# PIC32CX0525SG12084 register map
Vendor: Microchip Technology; Series: 0525SG12; File version: 0
CPU: CM4 r1p0, little endian, no MPU, no FPU, 3 interrupt priority bits, 172 interrupts
Registers are 32-bit, read-write, reset 0x0 unless marked. A register's access mark holds for its fields unless they carry their own. Offsets are from the block's base; [hi:lo] are bit positions.

## PWM0 — The PWM block generates an arbitrary duty cycle output at frequencies from less than 0.1 Hz to 24 MHz
Base 0x40005800; register names take the prefix PWM_
Same registers: PWM1 0x40005810, PWM4 0x40005840, PWM6 0x40005860, PWM7 0x40005870
0x00 CNT_ON — This field determines both the frequency and duty cycle of the PWM signal. Setting this field to a value of n will cause the On time of the PWM to be n+1 cycles of the PWM Clock Source. When this field is set to zero and the PWMX_COUNTER_OFF_TIME is not set to zero, the PWM_OUTPUT is held low (Full Off).
0x04 CNT_OFF reset 0xFFFF — This field determine both the frequency and duty cycle of the PWM signal. Setting this field to a value of n will cause the Off time of the PWM to be n+1 cycles of the PWM Clock Source. When this field is set to zero, the PWM_OUTPUT is held high (Full On).
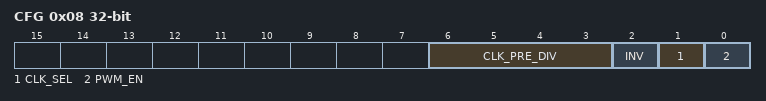
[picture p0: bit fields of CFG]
0x08 CFG — PWMx CONFIGURATION REGISTER
  [6:3] CLK_PRE_DIV — The Clock source for the 16-bit down counter (see PWMx Counter ON Time Register and PWMx Counter OFF Time Register) is determined by bit D1 of this register. The Clock source is then divided by the value of Pre-Divider+1 and the resulting signal determines the rate at which the down counter will be decremented. For example, a Pre-Divider value of 1 divides the input clock by 2 and a value of 2 divides the input clock by 3. A Pre-Divider of 0 will disable the Pre-Divider option.
  [2] INV — 1= PWM_OUTPUT ON State is active low; 0=PWM_OUTPUT ON State is active high.
  [1] CLK_SEL — This bit determines the clock source used by the PWM duty cycle and frequency control logic. 1=CLOCK_LOW. 0=CLOCK_HIGH
  [0] PWM_EN — When the PWM_ENABLE is set to 0 the internal counters are reset and the internal state machine is set to the OFF state. In addition, the PWM_OUTPUT signal is set to the inactive state as determined by the Invert bit. The PWMx Counter ON Time Register and PWMx Counter OFF Time Register are not affected by the PWM_ENABLE bit and may be read and written while the PWM enable bit is 0. 1=Enabled (default); 0=Disabled (gates clocks to save power).

## PS2_0 — The four PS/2 Ports implementation eliminates the need to bit bang I/O ports to generate PS/2 traffic
Base 0x40009000; register names take the prefix PS2_
0x00 TX_DATA wo — Writes to bits 7:0 of this register start a transmission of the data in this register to the peripheral
0x00 RX_DATA ro reset 0xFF — Data received from a peripheral are recorded in this register in bits 7:0.
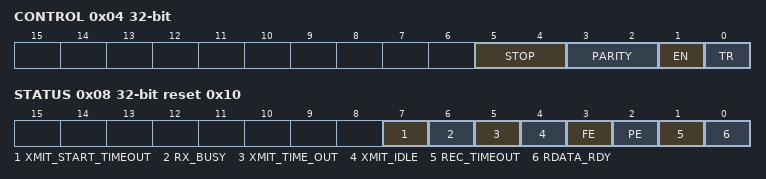
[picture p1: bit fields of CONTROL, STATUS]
0x04 CONTROL — PS2 Control Register
  [5:4] STOP — 00b=Receiver expects an active high stop bit. 01b=Receiver expects an active low stop bit. 10b=Receiver ignores the level of the Stop bit (11th bit is not interpreted as a stop bit). 11b=Reserved.
  [3:2] PARITY — 00b=Receiver expects Odd Parity (default). 01b=Receiver expects Even Parity. 10b=Receiver ignores level of the parity bit (10th bit is not interpreted as a parity bit). 11b=Reserved
  [1] EN — PS/2 Enable. 0=The PS/2 state machine is disabled. 1=The PS/2 state machine is enabled.
  [0] TR — PS/2 Transmit/Receive. 0=The P2/2 channel is enabled to receive data. 1=The PS2 channel is enabled to transmit data.
0x08 STATUS reset 0x10 — PS2 Status Register
  [7] XMIT_START_TIMEOUT — Transmit Start Timeout. 0=No transmit start timeout detected. 1=A start bit was not received within 25 ms following the transmit start event. The transmit start bit time-out condition is also indicated by the XMIT_TIMEOUT bit.
  [6] RX_BUSY — Receive Channel Busy. 0=The channel is idle. 1=The channel is actively receiving PS/2 data
  [5] XMIT_TIME_OUT — Transmitter Time-out. When the XMIT_TIMEOUT bit is set, the PS2_T/R bit is held clear, the PS/2 channel's CLK line is pulled low for a minimum of 300us until the PS/2 Status register is read.
  [4] XMIT_IDLE — Transmitter Idle. 0=The channel is actively transmitting PS/2 data. 1=The channel is not transmitting. A low to high transition on this bit generates a PS2 Activity interrupt.
  [3] FE — Framing Error
  [2] PE — Parity Error
  [1] REC_TIMEOUT — Receive Timeout. The REC_TIMEOUT bit is cleared when the Status Register is read. A low to high transition on this bit generates a PS2 Activity interrupt. (R/WC)
  [0] RDATA_RDY — Receive Data Ready. Reading the Receive Register clears this bit. A low to high transition on this bit generates a PS2 Activity interrupt.
